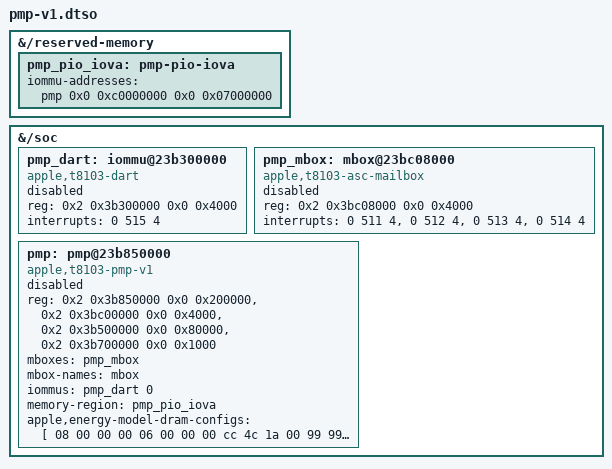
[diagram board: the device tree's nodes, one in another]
// SPDX-License-Identifier: GPL-2.0+ OR MIT
/*
 * Apple M1 (t8103) power management processor, PMP v1: lab experiment.
 *
 * Applied at run time by apple_pmp_v1_dt_setup() (pmp_v1_dt.c) when the
 * apple-pmp-v1 module loads, so nothing depends on the device tree the boot
 * loader passes. It adds the PMP, its DART and its mailbox at the t8103
 * addresses, all disabled, plus an IOVA-only reservation of the DART range
 * the firmware's MMIO windows use. It refers to nothing in the base tree
 * (which may have no __symbols__): the setup code adds interrupt-parent and
 * power-domains from the base tree and then enables the three nodes, which
 * creates their platform devices.
 *
 * Interrupt specifiers are AIC_IRQ (0), the AIC number, IRQ_TYPE_LEVEL_HIGH
 * (4). No "pmp" alias: m1n1 acts on that alias.
 */

/dts-v1/;
/plugin/;

/ {
	fragment@0 {
		target-path = "/reserved-memory";

		__overlay__ {
			/*
			 * IOVA-only: the firmware expects its MMIO windows at
			 * fixed DART addresses from 0xc0000000.
			 */
			pmp_pio_iova: pmp-pio-iova {
				iommu-addresses = <&pmp 0x0 0xc0000000 0x0 0x07000000>;
			};
		};
	};

	fragment@1 {
		target-path = "/soc";

		__overlay__ {
			#address-cells = <2>;
			#size-cells = <2>;

			pmp_dart: iommu@23b300000 {
				compatible = "apple,t8103-dart";
				reg = <0x2 0x3b300000 0x0 0x4000>;
				#iommu-cells = <1>;
				interrupts = <0 515 4>;
				status = "disabled";
			};

			pmp_mbox: mbox@23bc08000 {
				compatible = "apple,t8103-asc-mailbox", "apple,asc-mailbox-v4";
				reg = <0x2 0x3bc08000 0x0 0x4000>;
				interrupts = <0 511 4>, <0 512 4>, <0 513 4>, <0 514 4>;
				interrupt-names = "send-empty", "send-not-empty",
						  "recv-empty", "recv-not-empty";
				#mbox-cells = <0>;
				status = "disabled";
			};

			pmp: pmp@23b850000 {
				compatible = "apple,t8103-pmp-v1";
				reg = <0x2 0x3b850000 0x0 0x200000>,
				      <0x2 0x3bc00000 0x0 0x4000>,
				      <0x2 0x3b500000 0x0 0x80000>,
				      <0x2 0x3b700000 0x0 0x1000>;
				reg-names = "pmp", "asc", "sram", "pmgr";
				mboxes = <&pmp_mbox>;
				mbox-names = "mbox";
				iommus = <&pmp_dart 0>;
				memory-region = <&pmp_pio_iova>;
				/*
				 * energy-model-dram-configs of /arm-io/pmp/iop-pmp-nub in
				 * the MacBookAir10,1 (J313AP) ADT: four 128-byte tables keyed
				 * by DRAM capacity and vendor (8 GB/vendor 6, 8 GB/any,
				 * 16 GB/vendor 6, 16 GB/any). m1n1 does not pass it.
				 */
				apple,energy-model-dram-configs = [
					08 00 00 00 06 00 00 00 cc 4c 1a 00 99 99 00 00
					66 66 07 00 00 00 01 00 33 b3 08 00 00 80 58 00
					66 e6 54 00 33 33 0b 00 cc cc 00 00 66 66 17 00
					66 66 23 00 00 80 01 00 99 99 0f 00 66 e6 01 00
					33 b3 11 00 cc 4c b4 00 99 19 aa 00 00 80 14 00
					cc cc 00 00 cc cc 2e 00 cc cc 25 00 00 80 01 00
					33 33 12 00 66 e6 01 00 00 00 14 00 cc 4c f2 00
					33 33 d2 00 33 b3 16 00 cc cc 00 00 33 33 44 00
					08 00 00 00 ff 00 00 00 cc 4c 0f 00 cc 4c 00 00
					66 e6 05 00 00 00 01 00 33 33 07 00 66 66 6a 00
					66 e6 47 00 33 b3 09 00 00 80 00 00 66 66 17 00
					99 99 16 00 00 80 00 00 cc 4c 0c 00 cc cc 01 00
					00 80 0e 00 99 19 bd 00 33 b3 9b 00 33 33 10 00
					00 80 00 00 cc cc 2e 00 99 19 1a 00 00 80 00 00
					cc 4c 0f 00 cc cc 01 00 00 00 12 00 33 b3 0e 01
					33 33 cc 00 66 66 13 00 00 80 00 00 33 33 44 00
					10 00 00 00 06 00 00 00 cc cc 26 00 33 33 01 00
					cc cc 0e 00 33 b3 01 00 33 33 10 00 66 e6 6d 00
					00 80 66 00 cc 4c 16 00 33 b3 01 00 66 66 17 00
					33 33 35 00 cc cc 02 00 00 80 1c 00 00 80 03 00
					00 80 1e 00 cc cc e1 00 cc 4c ce 00 00 80 25 00
					33 b3 01 00 cc cc 2e 00 00 80 39 00 cc cc 02 00
					cc 4c 20 00 00 80 03 00 cc 4c 22 00 99 99 25 01
					99 99 fe 00 cc 4c 29 00 33 b3 01 00 33 33 44 00
					10 00 00 00 ff 00 00 00 66 e6 21 00 99 19 01 00
					66 e6 10 00 66 e6 01 00 33 33 13 00 00 00 75 00
					cc 4c 63 00 99 19 1c 00 cc 4c 01 00 66 66 17 00
					cc 4c 2e 00 cc cc 01 00 33 b3 1c 00 cc 4c 03 00
					99 99 1f 00 33 b3 f8 00 cc 4c d4 00 cc 4c 28 00
					cc 4c 01 00 cc cc 2e 00 33 b3 34 00 cc cc 01 00
					cc 4c 22 00 cc 4c 03 00 99 99 25 00 99 99 52 01
					00 00 14 01 00 00 2e 00 cc 4c 01 00 33 33 44 00
				];
				status = "disabled";
			};
		};
	};
};
